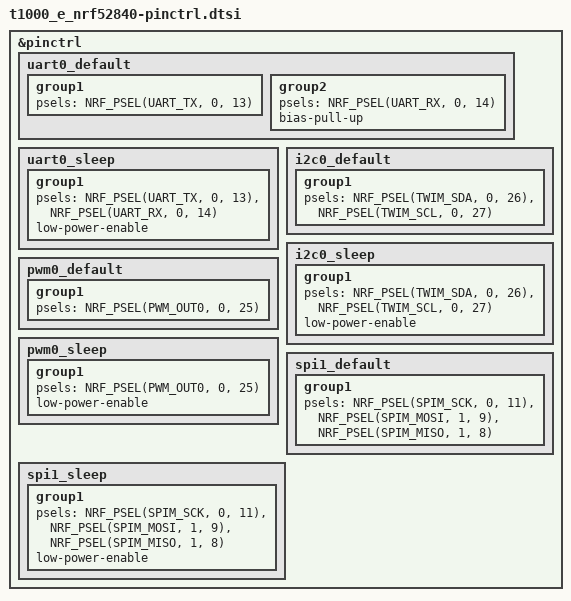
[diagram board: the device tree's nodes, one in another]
/*
 * Seeed Tracker T1000-E - Pin Control
 * Copyright (c) 2025 ZephCore
 * SPDX-License-Identifier: MIT
 *
 * Pin assignments from variant.h:
 * - SPI: SCK=P0.11, MISO=P1.08, MOSI=P1.09, NSS=P0.12 (for LR1110)
 * - I2C: SDA=P0.26, SCL=P0.27
 * - UART: TX=P0.13, RX=P0.14 (GPS L76K)
 * - LR1110: DIO1=P1.01, BUSY=P0.07, RESET=P1.10
 */

&pinctrl {
	/* GPS UART - L76K at 9600 baud */
	uart0_default: uart0_default {
		group1 {
			psels = <NRF_PSEL(UART_TX, 0, 13)>;
		};
		group2 {
			psels = <NRF_PSEL(UART_RX, 0, 14)>;
			bias-pull-up;
		};
	};

	uart0_sleep: uart0_sleep {
		group1 {
			psels = <NRF_PSEL(UART_TX, 0, 13)>,
			        <NRF_PSEL(UART_RX, 0, 14)>;
			low-power-enable;
		};
	};

	/* I2C0 for accelerometer */
	i2c0_default: i2c0_default {
		group1 {
			psels = <NRF_PSEL(TWIM_SDA, 0, 26)>,
			        <NRF_PSEL(TWIM_SCL, 0, 27)>;
		};
	};

	i2c0_sleep: i2c0_sleep {
		group1 {
			psels = <NRF_PSEL(TWIM_SDA, 0, 26)>,
			        <NRF_PSEL(TWIM_SCL, 0, 27)>;
			low-power-enable;
		};
	};

	/* PWM0 for buzzer on P0.25 */
	pwm0_default: pwm0_default {
		group1 {
			psels = <NRF_PSEL(PWM_OUT0, 0, 25)>;
		};
	};

	pwm0_sleep: pwm0_sleep {
		group1 {
			psels = <NRF_PSEL(PWM_OUT0, 0, 25)>;
			low-power-enable;
		};
	};

	/* SPI1 for LR1110 - CS controlled manually */
	spi1_default: spi1_default {
		group1 {
			psels = <NRF_PSEL(SPIM_SCK, 0, 11)>,
			        <NRF_PSEL(SPIM_MOSI, 1, 9)>,
			        <NRF_PSEL(SPIM_MISO, 1, 8)>;
		};
	};

	spi1_sleep: spi1_sleep {
		group1 {
			psels = <NRF_PSEL(SPIM_SCK, 0, 11)>,
			        <NRF_PSEL(SPIM_MOSI, 1, 9)>,
			        <NRF_PSEL(SPIM_MISO, 1, 8)>;
			low-power-enable;
		};
	};
};
